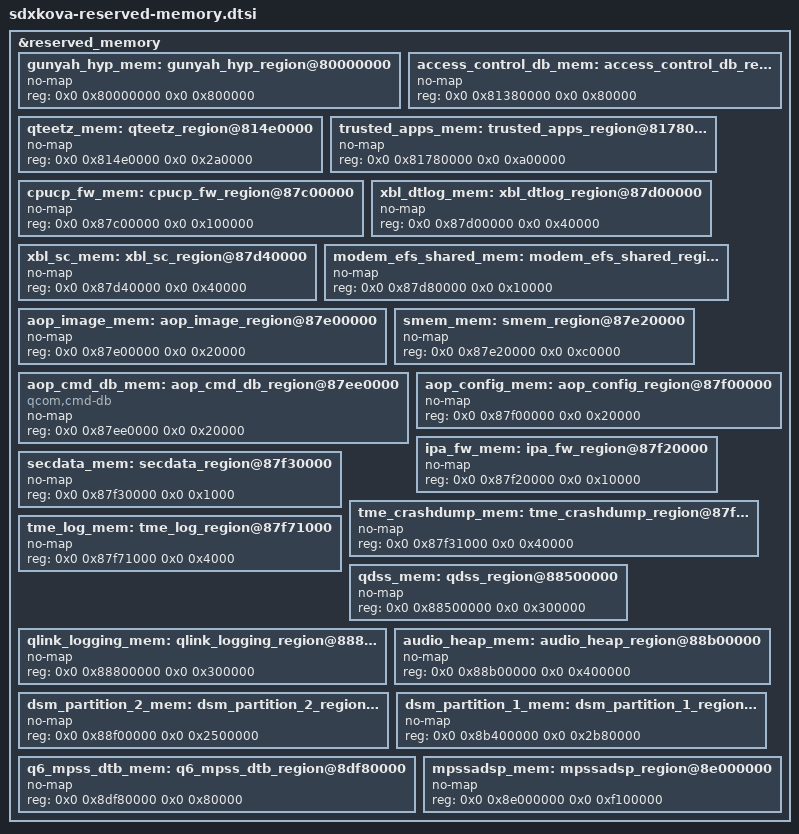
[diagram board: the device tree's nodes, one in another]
// SPDX-License-Identifier: BSD-3-Clause
/*
 * Copyright (c) 2024 Qualcomm Innovation Center, Inc. All rights reserved.
 */

&reserved_memory {
	#address-cells = <2>;
	#size-cells = <2>;
	ranges;

	gunyah_hyp_mem: gunyah_hyp_region@80000000 {
		no-map;
		reg = <0x0 0x80000000 0x0 0x800000>;
	};

	/* HYP elf package region at 0x80800000 to be shared with Linux */

	access_control_db_mem: access_control_db_region@81380000 {
		no-map;
		reg = <0x0 0x81380000 0x0 0x80000>;
	};

	qteetz_mem: qteetz_region@814e0000 {
		no-map;
		reg = <0x0 0x814e0000 0x0 0x2a0000>;
	};

	trusted_apps_mem: trusted_apps_region@81780000 {
		no-map;
		reg = <0x0 0x81780000 0x0 0xa00000>;
	};

	/* UEFI region at 0x87100000 is reclaimed by Linux */

	/* UEFI region at 0x87500000 is reclaimed by Linux */

	/* ABL region at 0x87900000 is reclaimed by Linux */

	/* XBL RAMdump at 0x87a00000 to be reused Linux */

	cpucp_fw_mem: cpucp_fw_region@87c00000 {
		no-map;
		reg = <0x0 0x87c00000 0x0 0x100000>;
	};

	xbl_dtlog_mem: xbl_dtlog_region@87d00000 {
		no-map;
		reg = <0x0 0x87d00000 0x0 0x40000>;
	};

	xbl_sc_mem: xbl_sc_region@87d40000 {
		no-map;
		reg = <0x0 0x87d40000 0x0 0x40000>;
	};

	modem_efs_shared_mem: modem_efs_shared_region@87d80000 {
		no-map;
		reg = <0x0 0x87d80000 0x0 0x10000>;
	};

	aop_image_mem: aop_image_region@87e00000 {
		no-map;
		reg = <0x0 0x87e00000 0x0 0x20000>;
	};

	smem_mem: smem_region@87e20000 {
		no-map;
		reg = <0x0 0x87e20000 0x0 0xc0000>;
	};

	aop_cmd_db_mem: aop_cmd_db_region@87ee0000 {
		compatible = "qcom,cmd-db";
		no-map;
		reg = <0x0 0x87ee0000 0x0 0x20000>;
	};

	aop_config_mem: aop_config_region@87f00000 {
		no-map;
		reg = <0x0 0x87f00000 0x0 0x20000>;
	};

	ipa_fw_mem: ipa_fw_region@87f20000 {
		no-map;
		reg = <0x0 0x87f20000 0x0 0x10000>;
	};

	secdata_mem: secdata_region@87f30000 {
		no-map;
		reg = <0x0 0x87f30000 0x0 0x1000>;
	};

	tme_crashdump_mem: tme_crashdump_region@87f31000 {
		no-map;
		reg = <0x0 0x87f31000 0x0 0x40000>;
	};

	tme_log_mem: tme_log_region@87f71000 {
		no-map;
		reg = <0x0 0x87f71000 0x0 0x4000>;
	};

	/* UEFI region at 0x87f75000 is reclaimed by Linux */

	qdss_mem: qdss_region@88500000 {
		no-map;
		reg = <0x0 0x88500000 0x0 0x300000>;
	};

	qlink_logging_mem: qlink_logging_region@88800000 {
		no-map;
		reg = <0x0 0x88800000 0x0 0x300000>;
	};

	audio_heap_mem: audio_heap_region@88b00000 {
		no-map;
		reg = <0x0 0x88b00000 0x0 0x400000>;
	};

	dsm_partition_2_mem: dsm_partition_2_region@88f00000 {
		no-map;
		reg = <0x0 0x88f00000 0x0 0x2500000>;
	};

	dsm_partition_1_mem: dsm_partition_1_region@8b400000 {
		no-map;
		reg = <0x0 0x8b400000 0x0 0x2b80000>;
	};

	q6_mpss_dtb_mem: q6_mpss_dtb_region@8df80000 {
		no-map;
		reg = <0x0 0x8df80000 0x0 0x80000>;
	};

	mpssadsp_mem: mpssadsp_region@8e000000 {
		no-map;
		reg = <0x0 0x8e000000 0x0 0xf100000>;
	};

	/* Linux kernel image is loaded at 0xa8000000 */

};
